# PIC32CX5109BZ31048 register map
Vendor: Microchip Technology; Series: PIC32CXBZ31; File version: 0
Microchip PIC32CX5109BZ31048 Microcontroller
CPU: CM4 r0p1, little endian, MPU, FPU, 3 interrupt priority bits, 43 interrupts
Registers are 32-bit, read-write, reset 0x0 unless marked. A register's access mark holds for its fields unless they carry their own. Offsets are from the block's base; lines under a group give offsets from that group; [hi:lo] are bit positions; {n}, {i} and the like mark numbered series; 'fields as' and 'values as' point back to an identical list; <NAME> marks a mode.

## Memory map
0x40000000 PAC size 0x40 — Peripheral Access Controller
0x40000400 FREQM size 0x14 — Frequency Meter
0x40000800 EIC size 0x3C — External Interrupt Controller
0x40000C00 SERCOM0 size 0x31 — Serial Communication Interface
0x40001000 SERCOM1 size 0x31
0x40001400 TC0 size 0x38 — Basic Timer Counter
0x40001800 TC1 size 0x38
0x40001C00 TC2 size 0x38
0x40002000 TC3 size 0x38
0x40002400 TC4 size 0x38
0x40002800 TC5 size 0x38
0x40002C00 TC6 size 0x38
0x40003000 TC7 size 0x38
0x40003400 TCC0 size 0x88 — Timer Counter Control
0x40003800 TCC1 size 0x88
0x40003C00 TCC2 size 0x88
0x41000000 DSU size 0x2000 — Device Service Unit
0x41002000 CMCC size 0x38 — Cortex M Cache Controller
0x41004000 DMAC size 0x1A0 — Direct Memory Access Controller
0x41006000 EVSYS size 0x27C — Event System Interface
0x41008000 RAMECC size 0x10
0x41010000 ZIGBEE — ZigBee MAC DOS
0x41011000 ARB size 0x1C — Radio Arbiter
0x41012000 BLE size 0x4BC
0x41014000 BTZBSYS size 0x2C — BT ZB Subsystem
0x42000000 QSPI size 0x48 — Quad SPI interface
0x42000400 SERCOM2 size 0x31
0x42001800 CCL size 0x10 — Configurable Custom Logic
0x42001C00 AC size 0x24 — Analog Comparators
0x42002400 HMATRIX2TOP size 0x130 — HSB Matrix
0x42010000 RTC size 0x84 — Real-Time Counter
0x42011000 DSCON size 0x14
0x43000000 SILEX size 0x1405C
0x44000000 CFG size 0x204
0x44000500 WDT size 0x10 — Watch Dog Timer
0x44000600 NVM size 0x100 — flash controller
0x44000800 PFW size 0x174 — flash wrapper
0x44000A00 CRU size 0x194
0x44000A00 RCON size 0x60
0x44000E00 DMT size 0x80 — Dead Man Timer
0x44001000 PPS size 0x2FC
0x44001400 ADCHS size 0xAB4 — 12-bit Analog to Digital Converter
0x44002400 CVD size 0x204 — Hardware CVD Controller Macro
0x44002A00 GPIOA size 0xE0 — GPIO
0x44002B00 GPIOB size 0xE0
0x44002C00 ROT size 0xC0C — Secure Root of Trust Macro
0x44003C00 DAC_CTRL size 0xC — Descriptive Title of Macro
0x44003E00 DGI_SPI size 0x54 — SPI DMA for DGI Macro
0x44012400 PCHE size 0x40 — this is the PCHE
0x44013E00 PMU size 0x64 — PMU SPI controller
0xE0000000 ITM size 0x1000 — Instrumentation Trace Macrocell
0xE0001000 DWT size 0x5C — Data Watchpoint and Trace Register
0xE000E000 SystemControl size 0xD8C — System Control Registers
0xE000E010 SysTick size 0x10 — System timer
0xE000E100 NVIC size 0xE04 — Nested Vectored Interrupt Controller
0xE000ED90 MPU size 0x2C — Memory Protection Unit
0xE000EDF0 CoreDebug size 0x10
0xE000EF30 FPU size 0x18 — Floating Point Unit
0xE0040000 TPI size 0xFD0 — Trace Port Interface Register
0xE0041000 ETM size 0x1000 — Embedded Trace Macrocell

## Interrupts
0 RTC
1 EIC
2 FREQM
3 NVM
4 CHANGE_NOTICE_A (GPIOA)
5 CHANGE_NOTICE_B (GPIOB)
6 DMAC_0_3 (DMAC)
7 DMAC_4_15 (DMAC)
8 EVSYS_0_3 (EVSYS)
9 EVSYS_4_11 (EVSYS)
10 PAC
11 RAMECC
12 SERCOM0
13 SERCOM1
14 TCC0
15 TCC1
16 TCC2
{n+17} TC{n} (n=0..7)
25 ADCHS_IRQ (ADCHS)
26 AC
27 SILEX_0 (SILEX)
28 SILEX_1 (SILEX)
29 QSPI
30 ZB_INT0 (ZIGBEE)
31 BT_INT0 (BLE)
32 BT_INT1 (BLE)
33 ARBITER (ARB)
34 ADCHS_FAULT (ADCHS)
35 ADCHS_FCC (ADCHS)
36 ADCHS_BGVR_RDY (ADCHS)
37 CLKI_WAKEUP_NMI (BLE)
38 CVD
39 DGI_SPI
40 SERCOM2
42 BT_LC (BLE)

## AC — Analog Comparators
Base 0x42001C00
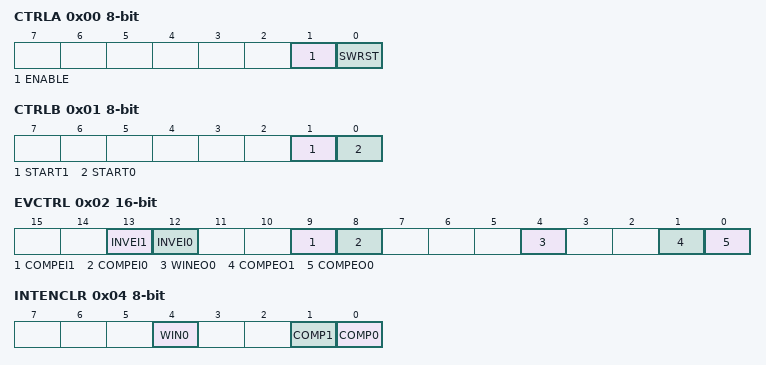
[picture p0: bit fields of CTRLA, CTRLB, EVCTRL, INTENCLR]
0x00 CTRLA 8-bit — Control A
  [1] ENABLE
  [0] SWRST — Software Reset
0x01 CTRLB 8-bit wo — Control B
  [1] START1 — Comparator 1 Start Comparison
  [0] START0 — Comparator 0 Start Comparison
0x02 EVCTRL 16-bit — Event Control
  [13] INVEI1 — Comparator 1 Input Event Invert Enable
  [12] INVEI0 — Comparator 0 Input Event Invert Enable
  [9] COMPEI1 — Comparator 1 Event Input Enable
  [8] COMPEI0 — Comparator 0 Event Input Enable
  [4] WINEO0 — Window 0 Event Output Enable
  [1] COMPEO1 — Comparator 1 Event Output Enable
  [0] COMPEO0 — Comparator 0 Event Output Enable
0x04 INTENCLR 8-bit — Interrupt Enable Clear
  [4] WIN0 — Window 0 Interrupt Enable
  [1] COMP1 — Comparator 1 Interrupt Enable
  [0] COMP0 — Comparator 0 Interrupt Enable
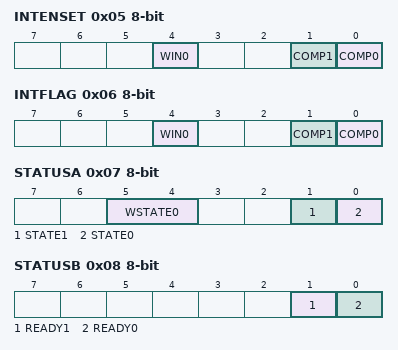
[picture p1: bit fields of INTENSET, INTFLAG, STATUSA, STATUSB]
0x05 INTENSET 8-bit — Interrupt Enable Set
  fields as INTENCLR
0x06 INTFLAG 8-bit — Interrupt Flag Status and Clear
  [4] WIN0 — Window 0
  [1] COMP1 — Comparator 1
  [0] COMP0 — Comparator 0
0x07 STATUSA 8-bit ro
  [5:4] WSTATE0 — Window 0 Current State
    0=ABOVE (Signal is above window); 1=INSIDE (Signal is inside window); 2=BELOW (Signal is below window)
  [1] STATE1 — Comparator 1 Current State
  [0] STATE0 — Comparator 0 Current State
0x08 STATUSB 8-bit ro
  [1] READY1 — Comparator 1 Ready
  [0] READY0 — Comparator 0 Ready
0x09 DBGCTRL 8-bit — Debug Control
  [0] DBGRUN — Debug Run
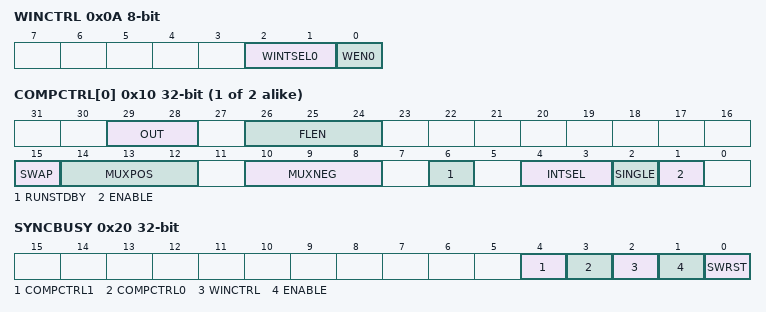
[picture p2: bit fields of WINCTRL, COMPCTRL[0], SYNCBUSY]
0x0A WINCTRL 8-bit — Window Control
  [2:1] WINTSEL0 — Window 0 Interrupt Selection
    0=ABOVE (Interrupt on signal above window); 1=INSIDE (Interrupt on signal inside window); 2=BELOW (Interrupt on signal below window); 3=OUTSIDE (Interrupt on signal outside window)
  [0] WEN0 — Window 0 Mode Enable
{0xC+i} SCALER[{i}] (i=0..1) 8-bit — Scaler n
  [5:0] VALUE — Scaler Value
{0x10+4i} COMPCTRL[{i}] (i=0..1) — Comparator Control n
  [29:28] OUT — Output
    0=OFF (The output of COMPn is not routed to the COMPn I/O port); 1=ASYNC (The asynchronous output of COMPn is routed to the COMPn I/O port); 2=SYNC (The synchronous output (including filtering) of COMPn is routed to the COMPn I/O port)
  [26:24] FLEN — Filter Length
    0=OFF (No filtering); 1=MAJ3 (3-bit majority function (2 of 3)); 2=MAJ5 (5-bit majority function (3 of 5))
  [15] SWAP — Swap Inputs and Invert
  [14:12] MUXPOS — Positive Input Mux Selection
    {v}=PIN{v} (I/O pin {v}) (v=0..3); 4=VSCALE (VDD Scaler)
  [10:8] MUXNEG — Negative Input Mux Selection
    {v}=PIN{v} (I/O pin {v}) (v=0..3); 4=GND (Ground); 5=VSCALE (VDD scaler); 6=BANDGAP (Internal bandgap voltage); 7=DAC (DAC output)
  [6] RUNSTDBY — Run in Standby
  [4:3] INTSEL — Interrupt Selection
    0=TOGGLE (Interrupt on comparator output toggle); 1=RISING (Interrupt on comparator output rising); 2=FALLING (Interrupt on comparator output falling); 3=EOC (Interrupt on end of comparison (single-shot mode only))
  [2] SINGLE — Single-Shot Mode
  [1] ENABLE
0x20 SYNCBUSY ro — Synchronization Busy
  [4] COMPCTRL1 — COMPCTRL 1 Synchronization Busy
  [3] COMPCTRL0 — COMPCTRL 0 Synchronization Busy
  [2] WINCTRL — WINCTRL Synchronization Busy
  [1] ENABLE — Enable Synchronization Busy
  [0] SWRST — Software Reset Synchronization Busy

## Notices in the file
Copyright (c) 2023 Microchip Technology Inc.
SPDX-License-Identifier: Apache-2.0
Licensed under the Apache License, Version 2.0 (the "License");
you may not use this file except in compliance with the License.
You may obtain a copy of the License at
http://www.apache.org/licenses/LICENSE-2.0
Unless required by applicable law or agreed to in writing, software
distributed under the License is distributed on an "AS IS" BASIS,
WITHOUT WARRANTIES OR CONDITIONS OF ANY KIND, either express or implied.
See the License for the specific language governing permissions and
limitations under the License.
